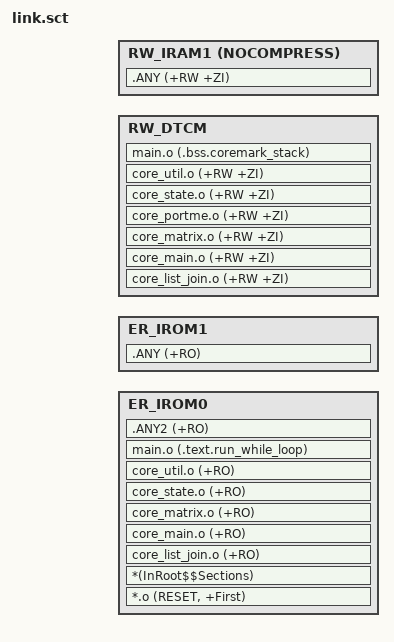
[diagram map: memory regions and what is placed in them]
#! armclang -E --target=arm-arm-none-eabi -mcpu=cortex-m33 -xc -I $SDK_ROOT/drivers/cmsis/sf32lb58x 
#include "rtconfig.h"
#include "mem_map.h"

; *************************************************************
; *** Scatter-Loading Description File generated by uVision ***
; *************************************************************

LR_IROM1 LCPU_RAM_CODE_START_ADDR LCPU_RAM_CODE_SIZE {    ; load region size_region
  ER_IROM0 LCPU_RAM_CODE_START_ADDR LPSYS_ITCM_SIZE  {  ; load address = execution address
   *.o (RESET, +First)
   *(InRoot$$Sections)
   core_list_join.o (+RO)
   core_main.o (+RO)
   core_matrix.o (+RO)
   core_state.o (+RO)
   core_util.o (+RO)
   main.o (.text.run_while_loop)
   .ANY2 (+RO)
  }
  ER_IROM1 +0   {  ; load address = execution address
   .ANY (+RO)
  }
  ScatterAssert((ImageLength(ER_IROM0)+ImageLength(ER_IROM1))<LCPU_RAM_CODE_SIZE)

  RW_DTCM LPSYS_DTCM_BASE LPSYS_DTCM_SIZE  {  ; RW data
   core_list_join.o (+RW +ZI)
   core_main.o (+RW +ZI)
   core_matrix.o (+RW +ZI)
   core_portme.o (+RW +ZI)
   core_state.o (+RW +ZI)
   core_util.o (+RW +ZI)  
   main.o (.bss.coremark_stack)
  }

  RW_IRAM1 AlignExpr(LPSYS_RAM_BASE+LCPU_RAM_CODE_SIZE, 16) ALIGN 16 NOCOMPRESS LCPU_RAM_DATA_SIZE  {  ; RW data
   .ANY (+RW +ZI)
  }
}

